AUTOSAR XML (schema 00049)
package /Company/Powertrain/Components
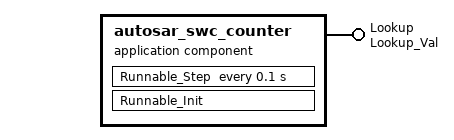
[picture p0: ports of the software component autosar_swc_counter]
  application sw component type autosar_swc_counter
    provide port Lookup: nonqueued-sender-com-spec{data-element=Lookup, init-value=0}, provided-interface=Lookup_Val
    behavior ASWC_IB: data-type-mapping=autosar_swc_counterDataTypeMappingsSet, handle-termination-and-restart=NO-SUPPORT
      constant-memorys:
        4 x parameter data prototype, all with sw-calibration-access=READ-WRITE:
          INC: category=VALUE, sw-addr-method=VAR, type=UInt8_my_qualifier_const, init-value=constant-reference={short-label=INC, constant=INC}
          LIMIT: category=VALUE, type=uint8, init-value=constant-reference={short-label=LIMIT, constant=LIMIT}
          RESET: category=VALUE, type=uint8, init-value=constant-reference={short-label=RESET, constant=RESET}
          SUMOUT: category=CURVE, type=Appl_SUMOUT, init-value=constant-reference={short-label=SUMOUT, constant=SUMOUT}
      ar-typed-per-instance-memorys:
        data autosar_swc_co_UnitDelay_DSTATE: category=VALUE, sw-addr-method=VAR, sw-calibration-access=READ-WRITE, type=uint8
      timing event Event_Step: start-on-event=Runnable_Step, period=0.1
      runnable Runnable_Init: sw-addr-method=CODE
      runnable Runnable_Step: sw-addr-method=CODE
        data-write-access:
          access OUT_Lookup_Lookup: accessed-variable=Lookup.Lookup
